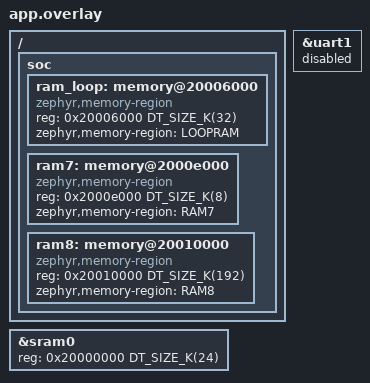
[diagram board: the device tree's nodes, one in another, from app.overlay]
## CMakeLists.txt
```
# SPDX-License-Identifier: Apache-2.0

cmake_minimum_required(VERSION 3.20.0)
find_package(Zephyr REQUIRED HINTS $ENV{ZEPHYR_BASE})
project(bus-replay-device)

target_sources(app PRIVATE
    src/main.c
    src/control.c
    src/capture.c
    src/capture_loop.S
)

if(CAPTURE_PROFILE)
    target_compile_definitions(app PRIVATE CAPTURE_PROFILE)
endif()
```

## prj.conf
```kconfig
CONFIG_LOG=y
CONFIG_LOG_BACKEND_SHOW_COLOR=n
CONFIG_BOOT_BANNER=n
CONFIG_CLOCK_CONTROL=y
```

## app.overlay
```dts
&sram0 {
    reg = <0x20000000 DT_SIZE_K(24)>;
};

/ {
    soc {
        ram_loop: memory@20006000 {
            compatible = "zephyr,memory-region", "mmio-sram";
            reg = <0x20006000 DT_SIZE_K(32)>;
            zephyr,memory-region = "LOOPRAM";
        };

        ram7: memory@2000e000 {
            compatible = "zephyr,memory-region", "mmio-sram";
            reg = <0x2000e000 DT_SIZE_K(8)>;
            zephyr,memory-region = "RAM7";
        };

        ram8: memory@20010000 {
            compatible = "zephyr,memory-region", "mmio-sram";
            reg = <0x20010000 DT_SIZE_K(192)>;
            zephyr,memory-region = "RAM8";
        };
    };
};

&uart1 {
    status = "disabled";
};
```

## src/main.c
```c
/*
 * Bus replay capture device: boot, configuration over the SPI control binding, then the
 * capture loop until reset.
 */

#include <errno.h>
#include <stddef.h>
#include <stdint.h>

#include <zephyr/irq.h>
#include <zephyr/kernel.h>
#include <zephyr/sys/notify.h>
#include <zephyr/sys/onoff.h>
#include <zephyr/sys/util.h>
#include <zephyr/sys/util_macro.h>

#include <zephyr/drivers/clock_control/nrf_clock_control.h>

#include <zephyr/logging/log.h>
#include <zephyr/logging/log_core.h>
#include <zephyr/logging/log_ctrl.h>

#include <mdk/nrf52840.h>
#include <mdk/nrf52840_bitfields.h>
#include <nrfx.h>

#include "capture.h"
#include "control.h"


LOG_MODULE_REGISTER(BUS_REPLAY, LOG_LEVEL_INF);


#define DATA_TX_PIN 25 // P0.25
#define DATA_RX_PIN (32 + 2) // P1.02


static int hfxo_start(void);
static void channels_configure(void);
static void data_uart_configure(void);
static void dwt_start(void);


int main(void)
{
    const struct capture_config *cfg = NULL;
    uint32_t ticks = 0;
    int err = 0;

    err = hfxo_start();
    if (err < 0) {
        LOG_ERR("Failed to start HFXO! (err: %d)", err);
        return err;
    }

    channels_configure();
    data_uart_configure();
    dwt_start();
    control_init();
    LOG_INF("Ready, waiting for configuration");

    while (!control_service()) {
        k_yield();
    }

    cfg = control_config();
    capture_prepare(cfg);
    LOG_INF("Capture starting: rate %u Hz, C %u, channels 0x%04x, W %u", cfg->sample_rate,
            cfg->c, cfg->enabled, capture_record_width(cfg));

    // From here only fatal errors are logged, synchronously, with interrupts off until
    // the host's reset.
    LOG_PANIC();
    (void)irq_lock();
    err = capture_run(&ticks);
    LOG_ERR("Capture stopped at tick %u! (err: %d)", ticks, err);

    for (;;) {
    }
}


// Capture runs from the crystal oscillator; starts it and waits until it runs.
static int hfxo_start(void)
{
    struct onoff_manager *mgr = z_nrf_clock_control_get_onoff(CLOCK_CONTROL_NRF_SUBSYS_HF);
    struct onoff_client cli = {0};
    int res = 0;
    int err = 0;

    sys_notify_init_spinwait(&cli.notify);

    err = onoff_request(mgr, &cli);
    if (err < 0) {
        return err;
    }

    do {
        err = sys_notify_fetch_result(&cli.notify, &res);
    } while (err == -EAGAIN);

    if ((NRF_CLOCK->HFCLKSTAT & CLOCK_HFCLKSTAT_SRC_Msk) != CLOCK_HFCLKSTAT_SRC_Xtal) {
        return -EIO;
    }

    return res;
}


/*
 * Sense pins: inputs, input buffer connected, no pull. Replay pins keep their reset state
 * (input buffer disconnected, not driven).
 */
static void channels_configure(void)
{
    for (size_t i = 0; i < ARRAY_SIZE(channels); i++) {
        NRF_P0->PIN_CNF[channels[i].sense] =
            (GPIO_PIN_CNF_DIR_Input << GPIO_PIN_CNF_DIR_Pos) |
            (GPIO_PIN_CNF_INPUT_Connect << GPIO_PIN_CNF_INPUT_Pos) |
            (GPIO_PIN_CNF_PULL_Disabled << GPIO_PIN_CNF_PULL_Pos);
    }
}


// Data UART (UARTE1) at 1 Mbaud, 8N1, driven by registers. Zephyr's uart1 is disabled.
static void data_uart_configure(void)
{
    NRF_UARTE1->ENABLE = UARTE_ENABLE_ENABLE_Disabled;
    NRF_P0->OUTSET = BIT(DATA_TX_PIN);
    NRF_P0->DIRSET = BIT(DATA_TX_PIN);
    NRF_UARTE1->PSEL.TXD = DATA_TX_PIN;
    NRF_UARTE1->PSEL.RXD = DATA_RX_PIN;
    NRF_UARTE1->PSEL.RTS = UARTE_PSEL_RTS_CONNECT_Msk;
    NRF_UARTE1->PSEL.CTS = UARTE_PSEL_CTS_CONNECT_Msk;
    NRF_UARTE1->BAUDRATE = UARTE_BAUDRATE_BAUDRATE_Baud1M;
    NRF_UARTE1->CONFIG = 0;
    NRF_UARTE1->INTENCLR = 0xFFFFFFFF;
    NRF_UARTE1->ENABLE = UARTE_ENABLE_ENABLE_Enabled;
    NRF_UARTE1->EVENTS_ENDTX = 0;
}


// The DWT cycle counter paces the ticks.
static void dwt_start(void)
{
    CoreDebug->DEMCR |= CoreDebug_DEMCR_TRCENA_Msk;
    DWT->CYCCNT = 0;
    DWT->CTRL |= DWT_CTRL_CYCCNTENA_Msk;
}
```

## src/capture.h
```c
/*
 * Capture settings and the capture loop, shared by the control side (hello, registers,
 * start checks) and main.
 */

#ifndef CAPTURE_H
#define CAPTURE_H

#include <stdint.h>


// Channels 0 to 5 are the cable's CH1 to CH6, all on P0 so one read samples them all.
#define CHANNEL_COUNT 6
#define DATA_CHANNEL_COUNT 1

// Ticks are paced in CPU cycles: sample rate = CPU_HZ / divisor.
#define CPU_HZ 64000000
#define MIN_DIVISOR 128
#define MAX_DIVISOR CPU_HZ

#define DATA_BAUD 1000000
#define UART_BITS_PER_BYTE 10

// Output ring: the spec's buffer, in RAM8.
#define OUT_SIZE (128 * 1024)

// C up to 2^27 - 1 keeps W at 4 bytes or less with any number of channels.
#define C_MIN 1
#define C_MAX ((1UL << 27) - 1)

// IRQ line to the Pi, driven by the control side and by the capture loop.
#define IRQ_PIN 26 // P0.26

#define CAPTURE_ERR_LAPPED 1
#define CAPTURE_ERR_HEARTBEAT_LATE 2


struct capture_config {
    uint32_t sample_rate;
    uint32_t c;
    uint16_t enabled;
    uint16_t split;
};

// One cable channel: the wire pair in one J12 column.
struct channel {
    uint8_t sense; // P0 pin, bottom row
    uint8_t replay; // P0 pin, top row, not driven
    const char *name;
};


extern const struct channel channels[CHANNEL_COUNT];


uint32_t capture_record_width(const struct capture_config *cfg);
uint32_t capture_heartbeat_size(const struct capture_config *cfg);
void capture_prepare(const struct capture_config *cfg);
int capture_run(uint32_t *ticks);

#endif
```

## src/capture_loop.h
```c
/*
 * Shared by capture.c and capture_loop.S: step numbers and the offsets of the fields the
 * assembly loop uses in struct capture. capture.c checks the offsets at build time.
 */

#ifndef CAPTURE_LOOP_H
#define CAPTURE_LOOP_H

/*
 * Cleanup steps. ST_SCAN to ST_SCAN_DROP run inline in the assembly loop; the others
 * are C functions in capture.c.
 */
#define ST_SCAN 0
#define ST_RECORD 1
#define ST_ENCODE 2
#define ST_CRC 3
#define ST_SCAN_DROP 4
#define ST_FIRST 5
#define ST_HEARTBEAT_NOW 6
#define ST_RECORD_SLOW 7
#define ST_WRITE 8
#define ST_CHECK 9
#define ST_FLUSH_START 10
#define ST_HEARTBEAT 11
#define ST_HEARTBEAT_PACK 12
#define ST_HEARTBEAT_TRY 13
#define ST_LOSS_END 14
#define ST_FLUSH 15
#define ST_FLUSH_END 16
#define ST_SNAP 17
#define ST_STOP 18
#define ST_COUNT 19

#define RAW_BITS 12
#define RAW_SIZE (1 << RAW_BITS)
#define OUT_BITS 17
#define SCAN_MAX 3
#define HK_MASK 15
#define CRC_PER_STEP 2

// struct capture, first fields, all 32-bit.
#define CAP_TICK 0
#define CAP_MASK 4
#define CAP_HK 8
#define CAP_CHANGED 12
#define CAP_CUR 16
#define CAP_RAW 20
#define CAP_WR 24
#define CAP_RD 28
#define CAP_CRC 32
#define CAP_CRC_POS 36
#define CAP_ROOM_LIMIT 40
#define CAP_WIDTH 44
#define CAP_TAG_BITS 48
#define CAP_HB_SEQ 52
#define CAP_HB_TICK 56
#define CAP_GAP 60
#define CAP_HB_PENDING 64
#define CAP_LOSS_OPEN 68
#define CAP_OUT 72
#define CAP_CRC8 76
#define CAP_LAG_MAX 80
#define CAP_AFTER_FLUSH 84
#define CAP_AFTER_CRC 88
#define CAP_SLICE_ADDS 92
#define CAP_LOSS_START 96
#define CAP_LOSS_END 100
#define CAP_DROP_LAG 104
#define CAP_DROP_ROOM 108
#define CAP_HB_LEN 112
#define CAP_MAX_LATE 116
#define CAP_SLICES 120
#define SLICES 8
#define SLICE_FLUSH_AT 128
#define CAP_TAG (CAP_SLICES + 4 * SLICES)
#define CAP_REF_SEQ (CAP_TAG + 32)
#define CAP_REF_TICK (CAP_REF_SEQ + 4 * 32)
#define CAP_STEPS (CAP_REF_TICK + 4 * 32)
#define CAP_HK_STEPS (CAP_STEPS + 4 * ST_COUNT)

// struct debug_counters, profile tables (CAPTURE_PROFILE builds).
#define DBG_STEP_MAX 44
#define DBG_STEP_SUM (DBG_STEP_MAX + 4 * 64)
#define DBG_STEP_COUNT (DBG_STEP_SUM + 4 * 64)

#endif
```

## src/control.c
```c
/*
 * Control channel before capture.
 *
 * SPIS1 on the MOD lines (SCK P1.13, MOSI P1.11, MISO P1.12, CSN P1.10), polled. Framing
 * is the spec's SPI binding: Length (2 bytes), message, CRC-16/CCITT-FALSE. IRQ is P0.26, driven low
 * while a message waits and released otherwise; the Pi's pull-up holds it high.
 *
 * The END_ACQUIRE short hands the semaphore back to the CPU after each transaction.
 * Neither ACQUIRED nor END proves a transaction happened (a refused one fires the short
 * too), so a transaction counts only when the CPU owns the semaphore (SEMSTAT) and rx_buf
 * no longer starts with Length 0xFFFF, which no host sends.
 */

#include <stdbool.h>
#include <stdint.h>
#include <string.h>

#include <zephyr/kernel.h>
#include <zephyr/sys/byteorder.h>
#include <zephyr/sys/util.h>
#include <zephyr/sys/util_macro.h>
#include <zephyr/toolchain.h>

#include <zephyr/logging/log.h>
#include <zephyr/logging/log_core.h>

#include <mdk/nrf52840.h>
#include <mdk/nrf52840_bitfields.h>
#include <nrfx.h>

#include "capture.h"
#include "control.h"


LOG_MODULE_REGISTER(CONTROL, LOG_LEVEL_INF);


#define SPI_SCK_PIN (32 + 13) // P1.13, MOD0
#define SPI_MOSI_PIN (32 + 11) // P1.11, MOD1
#define SPI_MISO_PIN (32 + 12) // P1.12, MOD2
#define SPI_CSN_PIN (32 + 10) // P1.10, MOD3

#define MSG_MAX 512
#define FRAME_MAX (MSG_MAX + 4)
#define QUEUE_SIZE 4

#define VERSION_MAJOR 1
#define VERSION_MINOR 0
#define MODEL "TH-1 MO bus replay"
#define FIRMWARE "0.1.0"

#define MSG_HELLO 0x01
#define MSG_CONFIG 0x02
#define MSG_CONFIG_REPLY 0x03

#define REG_CAPTURE 0x00
#define REG_SAMPLE_RATE 0x01
#define REG_C 0x02
#define REG_ENABLED 0x03
#define REG_SPLIT 0x04
#define REG_COUNT 5

#define TYPE_BOOL 0x00
#define TYPE_U32 0x01
#define TYPE_CHANNEL_SET 0x02

#define KIND_ANY 0x00
#define KIND_RANGE 0x01
#define KIND_LIST 0x02
#define KIND_DIVIDER 0x03

#define FLAG_WRITABLE BIT(0)

#define STATUS_ACCEPTED 0x00
#define STATUS_UNKNOWN 0x01
#define STATUS_LENGTH 0x03
#define STATUS_NOT_ALLOWED 0x04
#define STATUS_STARTED 0x05
#define STATUS_RATE 0x06
#define STATUS_C_SHORT 0x07
#define STATUS_NO_CHANNEL 0x08
#define STATUS_SPLIT 0x09

#define CHANNEL_SET_SIZE DIV_ROUND_UP(CHANNEL_COUNT, 8)
#define CHANNEL_SET_MASK (BIT(CHANNEL_COUNT) - 1)

#define DEFAULT_SAMPLE_RATE 500000
#define DEFAULT_C 1000
#define DEFAULT_ENABLED 0x0F // CH1 to CH4


struct message {
    uint16_t len;
    uint8_t data[MSG_MAX];
};

struct writer {
    uint8_t *buf;
    uint32_t len;
};


static void spis_configure(void);
static void irq_line_set(bool asserted);
static void rx_handle(uint32_t amount);
static void config_handle(const uint8_t *msg, uint32_t len);
static uint8_t config_write(uint8_t reg, const uint8_t *value, uint32_t len, const char **text);
static uint8_t start_check(const char **text);
static uint32_t reg_value_put(uint8_t reg, uint8_t *out);
static uint32_t channel_set_get(const uint8_t *in);
static void channel_set_put(uint32_t v, uint8_t *out);
static void tx_prepare(void);
static void hello_queue(void);
static void put_u8(struct writer *w, uint8_t v);
static void put_u16(struct writer *w, uint16_t v);
static void put_u32(struct writer *w, uint32_t v);
static void put_str(struct writer *w, const char *s);
static struct message *queue_tail_slot(void);
static void queue_push(void);
static uint16_t crc16(const uint8_t *data, uint32_t len);


static uint8_t tx_buf[FRAME_MAX] __attribute__((section("RAM8")));
static uint8_t rx_buf[FRAME_MAX] __attribute__((section("RAM8")));

static struct message queue[QUEUE_SIZE];
static uint32_t queue_head;
static uint32_t queue_tail;
static uint32_t tx_len; // Bytes of the frame in tx_buf, 0 if none.

static struct capture_config config = {
    .sample_rate = DEFAULT_SAMPLE_RATE,
    .c = DEFAULT_C,
    .enabled = DEFAULT_ENABLED,
    .split = 0,
};
static bool capture_on;


void control_init(void)
{
    spis_configure();
    hello_queue();
    tx_prepare();
    irq_line_set(true);
    NRF_SPIS1->TASKS_RELEASE = 1;
}


// One polling pass. True once capture was accepted and its reply clocked out (spec, Capture lifecycle).
bool control_service(void)
{
    if (!NRF_SPIS1->EVENTS_ACQUIRED) {
        return false;
    }
    NRF_SPIS1->EVENTS_ACQUIRED = 0;
    NRF_SPIS1->EVENTS_END = 0;

    if ((NRF_SPIS1->SEMSTAT & SPIS_SEMSTAT_SEMSTAT_Msk) != SPIS_SEMSTAT_SEMSTAT_CPU) {
        return false;
    }

    if (rx_buf[0] != 0xFF || rx_buf[1] != 0xFF) {
        NRF_SPIS1->STATUS = SPIS_STATUS_OVERREAD_Msk | SPIS_STATUS_OVERFLOW_Msk;

        // The device's message counts as sent only if all of it was clocked out.
        if (tx_len > 0 && NRF_SPIS1->TXD.AMOUNT >= tx_len) {
            queue_tail++;
        }
        rx_handle(NRF_SPIS1->RXD.AMOUNT);
    }

    if (capture_on && queue_head == queue_tail) {
        // Keep the semaphore: the capture loop takes the SPIS over from here.
        irq_line_set(false);
        return true;
    }

    tx_prepare();
    irq_line_set(queue_head != queue_tail);
    rx_buf[0] = 0xFF;
    rx_buf[1] = 0xFF;
    NRF_SPIS1->TASKS_RELEASE = 1;

    return false;
}


const struct capture_config *control_config(void)
{
    return &config;
}


static void spis_configure(void)
{
    // CSN pulled up so a released Pi pin (pull-down) does not select the slave.
    NRF_P1->PIN_CNF[SPI_CSN_PIN - 32] =
        (GPIO_PIN_CNF_INPUT_Connect << GPIO_PIN_CNF_INPUT_Pos) |
        (GPIO_PIN_CNF_PULL_Pullup << GPIO_PIN_CNF_PULL_Pos);
    NRF_P0->PIN_CNF[IRQ_PIN] = (GPIO_PIN_CNF_INPUT_Disconnect << GPIO_PIN_CNF_INPUT_Pos);
    NRF_P0->OUTCLR = BIT(IRQ_PIN);

    NRF_SPIS1->ENABLE = SPIS_ENABLE_ENABLE_Disabled;
    NRF_SPIS1->PSEL.SCK = SPI_SCK_PIN;
    NRF_SPIS1->PSEL.MOSI = SPI_MOSI_PIN;
    NRF_SPIS1->PSEL.MISO = SPI_MISO_PIN;
    NRF_SPIS1->PSEL.CSN = SPI_CSN_PIN;
    NRF_SPIS1->CONFIG = 0; // Mode 0, MSB first.
    NRF_SPIS1->DEF = 0xFF;
    NRF_SPIS1->ORC = 0x00;
    NRF_SPIS1->INTENCLR = 0xFFFFFFFF;
    NRF_SPIS1->SHORTS = SPIS_SHORTS_END_ACQUIRE_Msk;
    rx_buf[0] = 0xFF;
    rx_buf[1] = 0xFF;
    NRF_SPIS1->RXD.PTR = (uint32_t)rx_buf;
    NRF_SPIS1->RXD.MAXCNT = FRAME_MAX;
    NRF_SPIS1->EVENTS_END = 0;
    NRF_SPIS1->EVENTS_ACQUIRED = 0;
    NRF_SPIS1->ENABLE = SPIS_ENABLE_ENABLE_Enabled;
    NRF_SPIS1->TASKS_ACQUIRE = 1;

    while (!NRF_SPIS1->EVENTS_ACQUIRED) {
    }
    NRF_SPIS1->EVENTS_ACQUIRED = 0;
}


// Asserted: driven low. Released: pin disconnected, the Pi's pull-up holds it high.
static void irq_line_set(bool asserted)
{
    if (asserted) {
        NRF_P0->DIRSET = BIT(IRQ_PIN);
    } else {
        NRF_P0->DIRCLR = BIT(IRQ_PIN);
    }
}


static void rx_handle(uint32_t amount)
{
    uint32_t len = 0;

    if (amount < 2) {
        return;
    }

    len = sys_get_le16(rx_buf);
    if (len == 0) {
        return;
    }
    if (len > MSG_MAX || amount < len + 4) {
        LOG_WRN("Short host frame (len %u, amount %u)", len, amount);
        return;
    }
    if (crc16(rx_buf, len + 2) != sys_get_le16(&rx_buf[len + 2])) {
        LOG_WRN("Host frame CRC mismatch");
        return;
    }

    // A receiver ignores a message of a type it does not know (spec, Control messages).
    if (rx_buf[2] == MSG_CONFIG) {
        config_handle(&rx_buf[2], len);
    }
}


static void config_handle(const uint8_t *msg, uint32_t len)
{
    struct message *slot = queue_tail_slot();
    struct writer w = {0};
    const char *text = "";
    uint8_t reg = 0xFF;
    uint8_t status = 0;

    if (slot == NULL) {
        LOG_WRN("Reply queue full, dropping configuration reply!");
        return;
    }

    if (len < 2) {
        status = STATUS_LENGTH;
        text = "message too short";
    } else {
        reg = msg[1];
        status = config_write(reg, &msg[2], len - 2, &text);
    }

    w.buf = slot->data;
    put_u8(&w, MSG_CONFIG_REPLY);
    put_u8(&w, reg);
    put_u8(&w, status);
    put_str(&w, text);
    w.len += reg_value_put(reg, &w.buf[w.len]);
    slot->len = w.len;
    queue_push();
    LOG_INF("Write register 0x%02x: status 0x%02x", reg, status);
}


static uint8_t config_write(uint8_t reg, const uint8_t *value, uint32_t len, const char **text)
{
    uint32_t v = 0;
    uint8_t status = 0;

    if (reg >= REG_COUNT) {
        return STATUS_UNKNOWN;
    }
    if (capture_on) {
        return STATUS_STARTED;
    }

    switch (reg) {
    case REG_CAPTURE:
        if (len != 1) {
            return STATUS_LENGTH;
        }
        if (value[0] != 1) {
            *text = "capture can only be set on";
            return STATUS_NOT_ALLOWED;
        }
        status = start_check(text);
        if (status != STATUS_ACCEPTED) {
            return status;
        }
        capture_on = true;
        return STATUS_ACCEPTED;

    case REG_SAMPLE_RATE:
        if (len != 4) {
            return STATUS_LENGTH;
        }
        v = sys_get_le32(value);
        if (v == 0 || CPU_HZ % v != 0 || CPU_HZ / v < MIN_DIVISOR) {
            *text = "rate must be 64 MHz / d, d >= 128";
            return STATUS_NOT_ALLOWED;
        }
        config.sample_rate = v;
        return STATUS_ACCEPTED;

    case REG_C:
        if (len != 4) {
            return STATUS_LENGTH;
        }
        v = sys_get_le32(value);
        if (v < C_MIN || v > C_MAX) {
            return STATUS_NOT_ALLOWED;
        }
        config.c = v;
        return STATUS_ACCEPTED;

    case REG_ENABLED:
    case REG_SPLIT:
        if (len != CHANNEL_SET_SIZE) {
            return STATUS_LENGTH;
        }
        v = channel_set_get(value);
        if (v & ~CHANNEL_SET_MASK) {
            *text = "no such channel";
            return STATUS_NOT_ALLOWED;
        }
        if (reg == REG_ENABLED) {
            config.enabled = v;
        } else {
            config.split = v;
        }
        return STATUS_ACCEPTED;

    default:
        return STATUS_UNKNOWN;
    }
}


// Combined limits, checked on start (spec, Configuration).
static uint8_t start_check(const char **text)
{
    uint64_t send_time = 0;

    if (config.enabled == 0) {
        return STATUS_NO_CHANNEL;
    }
    if (POPCOUNT(config.split) > DATA_CHANNEL_COUNT - 1) {
        return STATUS_SPLIT;
    }

    // The register already rejects these rates; this is the spec's start check.
    if (CPU_HZ / config.sample_rate < MIN_DIVISOR) {
        return STATUS_RATE;
    }

    // C * (1 / rate) must cover two serial heartbeats at the data baud rate. With less,
    // one UART transfer can take most of C and a pending heartbeat can miss its slot.
    send_time = (uint64_t)capture_heartbeat_size(&config) * UART_BITS_PER_BYTE *
                config.sample_rate;
    if ((uint64_t)config.c * DATA_BAUD < 2 * send_time) {
        *text = "C shorter than two heartbeats";
        return STATUS_C_SHORT;
    }

    return STATUS_ACCEPTED;
}


// Writes the register's current value; returns its size, 0 for an unknown register.
static uint32_t reg_value_put(uint8_t reg, uint8_t *out)
{
    switch (reg) {
    case REG_CAPTURE:
        out[0] = capture_on ? 1 : 0;
        return 1;
    case REG_SAMPLE_RATE:
        sys_put_le32(config.sample_rate, out);
        return 4;
    case REG_C:
        sys_put_le32(config.c, out);
        return 4;
    case REG_ENABLED:
        channel_set_put(config.enabled, out);
        return CHANNEL_SET_SIZE;
    case REG_SPLIT:
        channel_set_put(config.split, out);
        return CHANNEL_SET_SIZE;
    default:
        return 0;
    }
}


// A channel set: ceil(N / 8) bytes, channel i in bit i % 8 of byte i / 8 (spec, Registers).
static uint32_t channel_set_get(const uint8_t *in)
{
    uint32_t v = 0;

    for (uint32_t i = 0; i < CHANNEL_SET_SIZE; i++) {
        v |= (uint32_t)in[i] << (8 * i);
    }

    return v;
}


static void channel_set_put(uint32_t v, uint8_t *out)
{
    for (uint32_t i = 0; i < CHANNEL_SET_SIZE; i++) {
        out[i] = (uint8_t)(v >> (8 * i));
    }
}


// Frames the head of the queue into tx_buf, or sends Length 0.
static void tx_prepare(void)
{
    const struct message *m = &queue[queue_tail % QUEUE_SIZE];
    uint16_t crc = 0;

    NRF_SPIS1->TXD.PTR = (uint32_t)tx_buf;
    if (queue_head == queue_tail) {
        sys_put_le16(0, tx_buf);
        tx_len = 0;
        NRF_SPIS1->TXD.MAXCNT = 2;
        return;
    }

    sys_put_le16(m->len, tx_buf);
    memcpy(&tx_buf[2], m->data, m->len);
    crc = crc16(tx_buf, m->len + 2);
    sys_put_le16(crc, &tx_buf[m->len + 2]);
    tx_len = m->len + 4;
    NRF_SPIS1->TXD.MAXCNT = tx_len;
}


static void hello_queue(void)
{
    struct message *slot = queue_tail_slot();
    struct writer w = {.buf = slot->data};

    put_u8(&w, MSG_HELLO);
    put_u8(&w, VERSION_MAJOR);
    put_u8(&w, VERSION_MINOR);
    put_str(&w, MODEL);
    put_str(&w, FIRMWARE);
    put_u8(&w, 8);
    put_u32(&w, NRF_FICR->DEVICEID[0]);
    put_u32(&w, NRF_FICR->DEVICEID[1]);
    put_u32(&w, OUT_SIZE);
    put_u16(&w, CHANNEL_COUNT);
    put_u8(&w, DATA_CHANNEL_COUNT);
    for (size_t i = 0; i < ARRAY_SIZE(channels); i++) {
        put_str(&w, channels[i].name);
    }
    put_u8(&w, REG_COUNT);

    put_u8(&w, REG_CAPTURE);
    put_u8(&w, TYPE_BOOL);
    put_u8(&w, FLAG_WRITABLE);
    put_str(&w, "capture");
    put_str(&w, "");
    put_u8(&w, KIND_LIST);
    put_u16(&w, 1);
    put_u8(&w, 1);
    w.len += reg_value_put(REG_CAPTURE, &w.buf[w.len]);

    put_u8(&w, REG_SAMPLE_RATE);
    put_u8(&w, TYPE_U32);
    put_u8(&w, FLAG_WRITABLE);
    put_str(&w, "sample rate");
    put_str(&w, "Hz");
    put_u8(&w, KIND_DIVIDER);
    put_u32(&w, CPU_HZ);
    put_u32(&w, MIN_DIVISOR);
    put_u32(&w, MAX_DIVISOR);
    w.len += reg_value_put(REG_SAMPLE_RATE, &w.buf[w.len]);

    put_u8(&w, REG_C);
    put_u8(&w, TYPE_U32);
    put_u8(&w, FLAG_WRITABLE);
    put_str(&w, "C");
    put_str(&w, "ticks");
    put_u8(&w, KIND_RANGE);
    put_u32(&w, C_MIN);
    put_u32(&w, C_MAX);
    w.len += reg_value_put(REG_C, &w.buf[w.len]);

    put_u8(&w, REG_ENABLED);
    put_u8(&w, TYPE_CHANNEL_SET);
    put_u8(&w, FLAG_WRITABLE);
    put_str(&w, "enabled channels");
    put_str(&w, "");
    put_u8(&w, KIND_ANY);
    w.len += reg_value_put(REG_ENABLED, &w.buf[w.len]);

    put_u8(&w, REG_SPLIT);
    put_u8(&w, TYPE_CHANNEL_SET);
    put_u8(&w, FLAG_WRITABLE);
    put_str(&w, "split");
    put_str(&w, "");
    put_u8(&w, KIND_ANY);
    w.len += reg_value_put(REG_SPLIT, &w.buf[w.len]);

    slot->len = w.len;
    queue_push();
    LOG_INF("Hello queued (%u bytes)", w.len);
}


static void put_u8(struct writer *w, uint8_t v)
{
    w->buf[w->len++] = v;
}


static void put_u16(struct writer *w, uint16_t v)
{
    sys_put_le16(v, &w->buf[w->len]);
    w->len += 2;
}


static void put_u32(struct writer *w, uint32_t v)
{
    sys_put_le32(v, &w->buf[w->len]);
    w->len += 4;
}


static void put_str(struct writer *w, const char *s)
{
    size_t len = strlen(s);

    put_u8(w, (uint8_t)len);
    memcpy(&w->buf[w->len], s, len);
    w->len += len;
}


// The next free queue slot, or NULL when the queue is full. queue_push() then adds it.
static struct message *queue_tail_slot(void)
{
    if (queue_head - queue_tail >= QUEUE_SIZE) {
        return NULL;
    }

    return &queue[queue_head % QUEUE_SIZE];
}


static void queue_push(void)
{
    queue_head++;
}


// CRC-16/CCITT-FALSE: polynomial 0x1021, initial 0xFFFF.
static uint16_t crc16(const uint8_t *data, uint32_t len)
{
    uint16_t crc = 0xFFFF;

    for (uint32_t i = 0; i < len; i++) {
        crc ^= (uint16_t)data[i] << 8;
        for (int b = 0; b < 8; b++) {
            crc = (crc & 0x8000) ? (uint16_t)((crc << 1) ^ 0x1021) : (uint16_t)(crc << 1);
        }
    }

    return crc;
}
```

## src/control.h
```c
/*
 * Control channel before capture: the SPI control binding (spec, SPI) on SPIS1, the
 * hello, and configuration messages.
 */

#ifndef CONTROL_H
#define CONTROL_H

#include <stdbool.h>

#include "capture.h"


void control_init(void);
bool control_service(void);
const struct capture_config *control_config(void);

#endif
```
